# f2838x_cm_systick_regs register map
Vendor: Texas Instruments
Peripheral module from a debugger description file (folder C2000).
Address unit: 16 bits
Registers are 32-bit, read-write, no defined reset value unless marked. A register's access mark holds for its fields unless they carry their own. Offsets are as the file gives them; lines under a group give offsets from that group; [hi:lo] are bit positions; {n}, {i} and the like mark numbered series; 'fields as' and 'values as' point back to an identical list; <NAME> marks a mode.

## SYSTICK — SYSTICK Registers
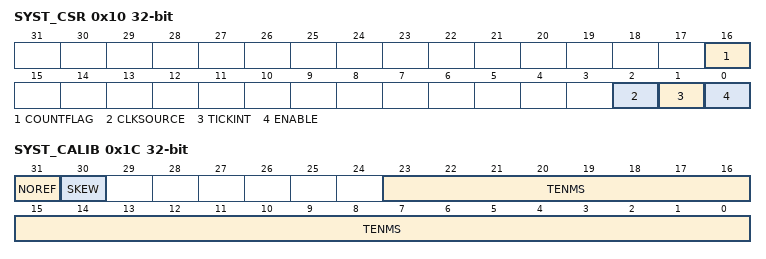
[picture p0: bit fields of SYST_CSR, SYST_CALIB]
0x10 SYST_CSR — Privileged a SysTick Control and Status Register
  [16] COUNTFLAG — timer counted to 0 since last read.
  [2] CLKSOURCE — Indicates the clock source
  [1] TICKINT — Enables SysTick exception request
  [0] ENABLE — Enables the counter
0x14 SYST_RVR — Privileged Unknown SysTick Reload Value Register
  [23:0] RELOAD — Counter reload value
0x18 SYST_CVR — Privileged Unknown SysTick Current Value Register
  [23:0] CURRENT — Current counter value
0x1C SYST_CALIB — Privileged -a SysTick Calibration Value Register
  [31] NOREF — Device provides a reference clock to the processor
  [30] SKEW — Indicates whether the TENMS value is exact
  [23:0] TENMS — Current counter value
